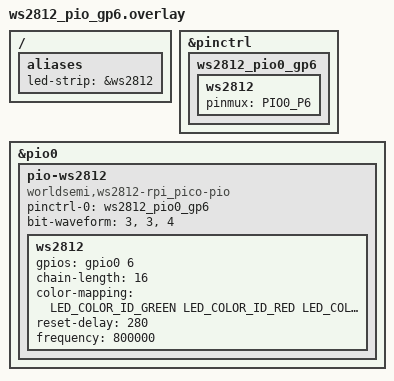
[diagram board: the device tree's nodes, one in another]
/* SPDX-License-Identifier: Apache-2.0 OR MIT */
/*
 * A 16-pixel WS2812 strip as led-strip on GP6, driven by PIO0 with
 * Zephyr's RP2 PIO driver, with the timing the RP2040 boards that carry
 * one use (boards/cytron/maker_nano_rp2040/maker_nano_rp2040.dts).
 */
#include <zephyr/dt-bindings/gpio/gpio.h>
#include <zephyr/dt-bindings/led/led.h>

/ {
	aliases {
		led-strip = &ws2812;
	};
};

&pinctrl {
	ws2812_pio0_gp6: ws2812_pio0_gp6 {
		ws2812 {
			pinmux = <PIO0_P6>;
		};
	};
};

&pio0 {
	status = "okay";

	pio-ws2812 {
		compatible = "worldsemi,ws2812-rpi_pico-pio";
		status = "okay";
		pinctrl-0 = <&ws2812_pio0_gp6>;
		pinctrl-names = "default";
		bit-waveform = <3>, <3>, <4>;

		ws2812: ws2812 {
			status = "okay";
			gpios = <&gpio0 6 GPIO_ACTIVE_HIGH>;
			chain-length = <16>;
			color-mapping = <LED_COLOR_ID_GREEN
					 LED_COLOR_ID_RED
					 LED_COLOR_ID_BLUE>;
			reset-delay = <280>;
			frequency = <800000>;
		};
	};
};
